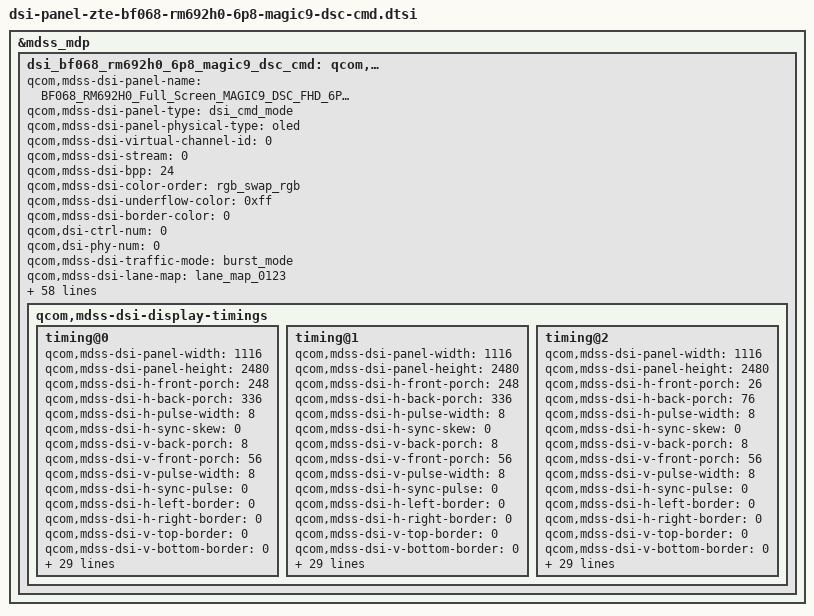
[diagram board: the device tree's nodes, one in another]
&mdss_mdp {
	dsi_bf068_rm692h0_6p8_magic9_dsc_cmd: qcom,mdss_dsi_bf068_rm692h0_6p8_magic9_dsc_cmd {
		qcom,mdss-dsi-panel-name =
				"BF068_RM692H0_Full_Screen_MAGIC9_DSC_FHD_6P8Inch";
		qcom,mdss-dsi-panel-type = "dsi_cmd_mode";
		qcom,mdss-dsi-panel-physical-type = "oled";
		qcom,mdss-dsi-virtual-channel-id = <0>;
		qcom,mdss-dsi-stream = <0>;
		qcom,mdss-dsi-bpp = <24>;
		qcom,mdss-dsi-color-order = "rgb_swap_rgb";
		qcom,mdss-dsi-underflow-color = <0xff>;
		qcom,mdss-dsi-border-color = <0>;
		qcom,dsi-ctrl-num = <0>;
		qcom,dsi-phy-num = <0>;
		qcom,mdss-dsi-traffic-mode = "burst_mode";
		qcom,mdss-dsi-lane-map = "lane_map_0123";
		qcom,mdss-dsi-bllp-eof-power-mode;
		qcom,mdss-dsi-bllp-power-mode;
		qcom,mdss-dsi-lane-0-state;
		qcom,mdss-dsi-lane-1-state;
		qcom,mdss-dsi-lane-2-state;
		qcom,mdss-dsi-lane-3-state;
		qcom,mdss-dsi-lp11-init;
		qcom,mdss-dsi-tx-eot-append;
		qcom,mdss-dsi-dma-trigger = "trigger_sw";
		qcom,mdss-dsi-mdp-trigger = "none";
		qcom,mdss-dsi-reset-sequence = <1 10>, <0 10>, <1 40>;
		qcom,mdss-dsi-te-pin-select = <1>;
		qcom,mdss-dsi-te-dcs-command = <1>;
		qcom,mdss-dsi-te-check-enable;
		qcom,mdss-dsi-te-using-te-pin;
		qcom,mdss-dsi-bl-min-level = <15>;
		qcom,mdss-dsi-bl-max-level = <3515>;
		qcom,mdss-dsi-bl-pmic-control-type = "bl_ctrl_dcs";
		qcom,mdss-dsi-panel-hdr-enabled;
		qcom,mdss-dsi-panel-hdr-color-primaries = <14500 15500 34015
			15980 13030 34670 6950 2565>;
		qcom,mdss-dsi-panel-peak-brightness = <6680000>;
		qcom,mdss-dsi-panel-blackness-level = <20>;
		qcom,mdss-pan-physical-width-dimension = <71>;
		qcom,mdss-pan-physical-height-dimension = <157>;
		qcom,bl-dcs-cmd-state = "dsi_lp_mode";
		qcom,bl-dsc-cmd-state = "dsi_lp_mode";
		qcom,mdss-dsi-display-timings {
			timing@0{
				qcom,mdss-dsi-panel-width = <1116>;
				qcom,mdss-dsi-panel-height = <2480>;
				qcom,mdss-dsi-h-front-porch = <248>;
				qcom,mdss-dsi-h-back-porch = <336>;
				qcom,mdss-dsi-h-pulse-width = <8>;
				qcom,mdss-dsi-h-sync-skew = <0>;
				qcom,mdss-dsi-v-back-porch = <8>;
				qcom,mdss-dsi-v-front-porch = <56>;
				qcom,mdss-dsi-v-pulse-width = <8>;
				qcom,mdss-dsi-h-sync-pulse = <0>;
				qcom,mdss-dsi-h-left-border = <0>;
				qcom,mdss-dsi-h-right-border = <0>;
				qcom,mdss-dsi-v-top-border = <0>;
				qcom,mdss-dsi-v-bottom-border = <0>;
				qcom,mdss-dsi-panel-framerate = <60>;
				qcom,mdss-mdp-transfer-time-us = <6235>;
				/*qcom,mdss-dsi-panel-clockrate = <1124510000>;*/

				qcom,mdss-dsi-on-command = [
					/* dimming */
					39 01 00 00 00 00 02 FE 98
					39 01 00 00 00 00 02 20 03
					/* aod lvd off */
					39 01 00 00 00 00 02 FE 42
					39 01 00 00 00 00 02 68 02
					/* fps 60 */
					39 01 00 00 00 00 02 FE 40
					39 01 00 00 00 00 02 0A C9// C7=60.54 C9=60.25 for 60HZ
					39 01 00 00 00 00 02 0B 17
					39 01 00 00 00 00 02 0C 35
					39 01 00 00 00 00 02 BE C9
					39 01 00 00 00 00 02 BF 11
					39 01 00 00 00 00 02 C0 C9
					39 01 00 00 00 00 02 BD 00
					/* HS CMD OFF */
					15 01 00 00 00 00 02 FE A1
					15 01 00 00 00 00 02 B3 7F
					/* vesa */
					15 01 00 00 00 00 02 FE 00
					15 01 00 00 00 00 02 FA 01
					/* BOE IP EN */
					39 01 00 00 00 00 02 FE 57
					39 01 00 00 00 00 02 C2 48
					39 01 00 00 00 00 02 FE 5A
					39 01 00 00 00 00 02 00 80
					39 01 00 00 00 00 02 FE 1A
					39 01 00 00 00 00 02 0D 64
					39 01 00 00 00 00 02 FE 40
					39 01 00 00 00 00 02 DC B8
					39 01 00 00 00 00 02 FE 42
					39 01 00 00 00 00 02 DA 82
					39 01 00 00 00 00 02 FE 20
					39 01 00 00 00 00 02 81 80
					/* ACL */
					39 01 00 00 00 00 02 FE 34
					39 01 00 00 00 00 02 47 03
					39 01 00 00 00 00 02 48 00
					39 01 00 00 00 00 02 00 00
					39 01 00 00 00 00 02 9F 5C
					39 01 00 00 00 00 02 A0 C4
					39 01 00 00 00 00 02 1C 00
					39 01 00 00 00 00 02 1D 10
					39 01 00 00 00 00 02 49 55
					39 01 00 00 00 00 02 FE 34
					39 01 00 00 00 00 02 1E 00
					39 01 00 00 00 00 02 1F 00
					39 01 00 00 00 00 02 20 00
					39 01 00 00 00 00 02 22 00
					39 01 00 00 00 00 02 21 70
					39 01 00 00 00 00 02 23 F8
					39 01 00 00 00 00 02 24 77
					39 01 00 00 00 00 02 25 F8
					39 01 00 00 00 00 02 26 F8
					39 01 00 00 00 00 02 2F 00
					39 01 00 00 00 00 02 30 00
					39 01 00 00 00 00 02 31 00
					39 01 00 00 00 00 02 32 00
					39 01 00 00 00 00 02 33 00
					39 01 00 00 00 00 02 34 00
					39 01 00 00 00 00 02 35 00
					39 01 00 00 00 00 02 36 40
					39 01 00 00 00 00 02 37 00
					39 01 00 00 00 00 02 38 7F
					39 01 00 00 00 00 02 39 00
					39 01 00 00 00 00 02 3A B6
					39 01 00 00 00 00 02 3B 00
					39 01 00 00 00 00 02 3D 00
					39 01 00 00 00 00 02 3F 00
					39 01 00 00 00 00 02 40 00
					39 01 00 00 00 00 02 41 00
					39 01 00 00 00 00 02 42 00
					/* ESD RECOVER */
					39 01 00 00 00 00 02 FE D4
					39 01 00 00 00 00 02 40 02
					39 01 00 00 00 00 02 FE FD
					39 01 00 00 00 00 02 80 06
					39 01 00 00 00 00 02 83 00
					39 01 00 00 00 00 02 FE A0
					39 01 00 00 00 00 02 06 36
					39 01 00 00 00 00 02 6E 00
					39 01 00 00 00 00 02 7c 15
					39 01 00 00 00 00 02 FE D0
					39 01 00 00 00 00 02 11 75
					39 01 00 00 00 00 02 92 03
					39 01 00 00 00 00 02 FE A1
					39 01 00 00 00 00 02 C3 87
					39 01 00 00 00 00 02 C4 FF
					39 01 00 00 00 00 02 C5 7F
					/* VESA 10bit */
					15 01 00 00 00 00 02 FE 00
					15 01 00 00 00 00 02 FA 01
					15 01 00 00 00 00 02 FE D2
					15 01 00 00 00 00 02 4F 00
					15 01 00 00 00 00 02 50 11
					15 01 00 00 00 00 02 51 ab
					15 01 00 00 00 00 02 52 30
					15 01 00 00 00 00 02 53 09
					15 01 00 00 00 00 02 54 b0
					15 01 00 00 00 00 02 55 04
					15 01 00 00 00 00 02 56 5c
					15 01 00 00 00 00 02 58 00
					15 01 00 00 00 00 02 59 14
					15 01 00 00 00 00 02 5a 02
					15 01 00 00 00 00 02 5b 2e
					15 01 00 00 00 00 02 5c 01
					15 01 00 00 00 00 02 5d 9a
					15 01 00 00 00 00 02 5e 19
					15 01 00 00 00 00 02 5f 01
					15 01 00 00 00 00 02 60 be
					15 01 00 00 00 00 02 61 00
					15 01 00 00 00 00 02 62 0a
					15 01 00 00 00 00 02 63 0c
					15 01 00 00 00 00 02 64 05
					15 01 00 00 00 00 02 65 0e
					15 01 00 00 00 00 02 66 05
					15 01 00 00 00 00 02 67 fd
					15 01 00 00 00 00 02 68 16
					15 01 00 00 00 00 02 69 00
					15 01 00 00 00 00 02 6a 10
					15 01 00 00 00 00 02 6b dc
					15 01 00 00 00 00 02 6c 07
					15 01 00 00 00 00 02 6d 10
					15 01 00 00 00 00 02 6e 20
					15 01 00 00 00 00 02 6f 00
					15 01 00 00 00 00 02 70 06
					15 01 00 00 00 00 02 71 0f
					15 01 00 00 00 00 02 72 0f
					15 01 00 00 00 00 02 73 33
					15 01 00 00 00 00 02 74 0e
					15 01 00 00 00 00 02 75 1c
					15 01 00 00 00 00 02 76 2a
					15 01 00 00 00 00 02 77 38
					15 01 00 00 00 00 02 78 46
					15 01 00 00 00 00 02 79 54
					15 01 00 00 00 00 02 7a 62
					15 01 00 00 00 00 02 7b 69
					15 01 00 00 00 00 02 7c 70
					15 01 00 00 00 00 02 7d 77
					15 01 00 00 00 00 02 7e 79
					15 01 00 00 00 00 02 7f 7b
					15 01 00 00 00 00 02 80 7d
					15 01 00 00 00 00 02 81 7e
					15 01 00 00 00 00 02 82 01
					15 01 00 00 00 00 02 83 c2
					15 01 00 00 00 00 02 84 22
					15 01 00 00 00 00 02 85 00
					15 01 00 00 00 00 02 86 2a
					15 01 00 00 00 00 02 87 40
					15 01 00 00 00 00 02 88 32
					15 01 00 00 00 00 02 89 be
					15 01 00 00 00 00 02 8a 3a
					15 01 00 00 00 00 02 8b fc
					15 01 00 00 00 00 02 8c 3a
					15 01 00 00 00 00 02 8d fa
					15 01 00 00 00 00 02 8e 3a
					15 01 00 00 00 00 02 8f f8
					15 01 00 00 00 00 02 90 3b
					15 01 00 00 00 00 02 91 38
					15 01 00 00 00 00 02 92 3b
					15 01 00 00 00 00 02 93 78
					15 01 00 00 00 00 02 94 3b
					15 01 00 00 00 00 02 95 76
					15 01 00 00 00 00 02 96 4b
					15 01 00 00 00 00 02 97 b6
					15 01 00 00 00 00 02 98 4b
					15 01 00 00 00 00 02 99 f6
					15 01 00 00 00 00 02 9a 4c
					15 01 00 00 00 00 02 9b 34
					15 01 00 00 00 00 02 9c 5c
					15 01 00 00 00 00 02 9d 74
					15 01 00 00 00 00 02 9e 8c
					15 01 00 00 00 00 02 9f f4
					15 01 00 00 00 00 02 a2 02
					15 01 00 00 00 00 02 a3 ba
					15 01 00 00 00 00 02 a4 00
					15 01 00 00 00 00 02 a5 00
					15 01 00 00 00 00 02 a6 00
					15 01 00 00 00 00 02 a7 00
					15 01 00 00 00 00 02 a9 00
					15 01 00 00 00 00 02 aa 00
					15 01 00 00 00 00 02 a0 a0
					/* ST swire control */
					15 01 00 00 00 00 02 FE 40
					15 01 00 00 00 00 02 24 54
					15 01 00 00 00 00 02 A9 14
					15 01 00 00 00 00 02 AD C8
					15 01 00 00 00 00 02 A5 20
					15 01 00 00 00 00 02 AC 04
					15 01 00 00 00 00 02 AE 70
					15 01 00 00 00 00 02 AF 4B
					15 01 00 00 00 00 02 B0 4B
					15 01 00 00 00 00 02 B2 4B
					15 01 00 00 00 00 02 B3 4F
					15 01 00 00 00 00 02 FE 26
					15 01 00 00 00 00 02 1D 26
					15 01 00 00 00 00 02 A4 1F
					/*8.8 PVGH*/
					15 01 00 00 00 00 02 FE 40
					15 01 00 00 00 00 02 3A E8
 					15 01 00 00 00 00 02 3B E8
					15 01 00 00 00 00 02 FE 42
					15 01 00 00 00 00 02 81 E8
					15 01 00 00 00 00 02 82 E8
					/* init code */
					15 01 00 00 00 00 02 FE 00
					15 01 00 00 00 00 02 C2 08
					15 01 00 00 00 00 02 36 00
					15 01 00 00 00 00 02 35 00
					15 01 00 00 00 00 02 53 20
					39 01 00 00 00 00 03 51 00 00
15 01 00 00 00 00 02 FE 60
15 01 00 00 00 00 02 AE 00
15 01 00 00 00 00 02 B3 00
15 01 00 00 00 00 02 B8 FF
15 01 00 00 00 00 02 BA FF
15 01 00 00 00 00 02 C7 CB
15 01 00 00 00 00 02 C8 CB
15 01 00 00 00 00 02 DB CB
15 01 00 00 00 00 02 DC CB
15 01 00 00 00 00 02 FE 00
					05 01 00 00 64 00 01 11
					05 01 00 00 14 00 01 29
					];
				qcom,mdss-dsi-off-command = [
15 01 00 00 00 00 02 FE 76
15 01 00 00 00 00 02 00 04

15 01 00 00 00 00 02 09 28
15 01 00 00 00 00 02 0A 00
15 01 00 00 00 00 02 0B 00
15 01 00 00 00 00 02 0C 49
15 01 00 00 00 00 02 0D 76
15 01 00 00 00 00 02 0E 17

15 01 00 00 00 00 02 49 FF
15 01 00 00 00 00 02 4A 01
15 01 00 00 00 00 02 4B 01
15 01 00 00 00 00 02 4C FE
15 01 00 00 00 00 02 4D 60
15 01 00 00 00 00 02 4E AE
15 01 00 00 00 00 02 4F 28
15 01 00 00 00 00 02 50 B3
15 01 00 00 00 00 02 51 28
15 01 00 00 00 00 02 52 B8
15 01 00 00 00 00 02 53 F9
15 01 00 00 00 00 02 54 BA
15 01 00 00 00 00 02 55 9F
15 01 00 00 00 00 02 56 C7
15 01 00 00 00 00 02 58 CF
15 01 00 00 00 00 02 59 C8
15 01 00 00 00 00 02 5A CF
15 01 00 00 00 00 02 5B DB
15 01 00 00 00 00 02 5C CF
15 01 00 00 00 00 02 5D DC
15 01 00 00 00 00 02 5E CF
15 01 00 00 00 00 02 5F FE
15 01 00 00 00 00 02 60 00
					15 01 00 00 14 00 02 FE 00
					05 01 00 00 93 00 01 28
					05 01 00 00 14 00 01 10
				];
				qcom,mdss-dsi-on-command-state = "dsi_lp_mode";
				qcom,mdss-dsi-off-command-state = "dsi_lp_mode";

				qcom,mdss-dsi-lp1-command = [
					15 01 00 00 00 00 02 FE 00
					05 01 00 00 14 00 01 39
				];
				qcom,mdss-dsi-lp1-command-state =
					"dsi_lp_mode";
				qcom,mdss-dsi-nolp-command = [
					15 01 00 00 00 00 02 FE 00
					39 01 00 00 00 00 03 51 00 00
					05 01 00 00 00 00 01 38
				];
				qcom,mdss-dsi-nolp-command-state =
					"dsi_lp_mode";
				qcom,mdss-dsi-timing-switch-command = [
					39 00 00 40 00 00 02 FE 40
					39 00 00 40 00 00 02 bd 00
					39 00 00 40 00 00 02 FE 5A
					39 00 00 40 00 00 0D 49 5E FF F0 FF FF FF F0 FF FF 00 FD FD
					39 00 00 40 00 00 03 58 16 FA
					39 00 00 40 00 00 05 5E 0F 0F 0F 05
					39 00 00 40 00 00 04 66 00 00 00
					39 00 00 40 00 00 03 6E 00 00
					39 00 00 40 00 00 03 7E 00 00
					39 00 00 40 00 00 04 92 4E 22 1F
					39 00 00 40 00 00 05 99 2D 24 0C 00
					39 00 00 40 00 00 04 9E 20 20 20
					39 00 00 40 00 00 03 A2 10 03
					39 00 00 40 00 00 02 A7 10
					39 00 00 40 00 00 03 A9 10 0D
					39 00 00 40 00 00 02 AC 00
					39 00 00 40 00 00 06 B0 08 08 05 05 00
					39 00 00 40 00 00 06 B8 09 09 05 00 00
					39 00 00 40 00 00 05 C0 08 08 03 00
					39 00 00 40 00 00 04 C8 06 06 02
					39 00 00 40 00 00 02 EA 16
					39 00 00 40 00 00 02 FE 5B
					39 00 00 40 00 00 02 2B 4B
					39 00 00 40 00 00 02 2D 24
					39 00 00 40 00 00 02 2F 1F
					39 00 00 40 00 00 0D 30 1F 3F 3F 38 32 24 0C 00 00 25 25 1D
					39 00 00 40 00 00 02 3D 11
					39 00 00 40 00 00 02 3F 07
					39 00 00 40 00 00 0A 40 04 00 00 1A 1A 0E 08 03 00
					39 00 00 40 00 00 05 4B 08 08 08 08
					39 00 00 40 00 00 02 50 00
					39 00 00 40 00 00 05 53 09 09 05 02
					39 00 00 40 00 00 02 58 00
					39 00 00 40 00 00 06 5C 08 08 04 01 00
					39 00 00 40 00 00 05 64 07 07 03 01
					39 00 00 00 00 00 02 FE 00
				];
				qcom,mdss-dsi-timing-switch-command-state =
				"dsi_lp_mode";
				qcom,compression-mode = "dsc";
				qcom,mdss-dsc-slice-height = <20>;
				qcom,mdss-dsc-slice-width = <558>;
				qcom,mdss-dsc-slice-per-pkt = <2>;
				qcom,mdss-dsc-bit-per-component = <10>;
				qcom,mdss-dsc-bit-per-pixel = <10>;
				qcom,mdss-dsc-block-prediction-enable;
			};
			timing@1{
				qcom,mdss-dsi-panel-width = <1116>;
				qcom,mdss-dsi-panel-height = <2480>;
				qcom,mdss-dsi-h-front-porch = <248>;
				qcom,mdss-dsi-h-back-porch = <336>;
				qcom,mdss-dsi-h-pulse-width = <8>;
				qcom,mdss-dsi-h-sync-skew = <0>;
				qcom,mdss-dsi-v-back-porch = <8>;
				qcom,mdss-dsi-v-front-porch = <56>;
				qcom,mdss-dsi-v-pulse-width = <8>;
				qcom,mdss-dsi-h-sync-pulse = <0>;
				qcom,mdss-dsi-h-left-border = <0>;
				qcom,mdss-dsi-h-right-border = <0>;
				qcom,mdss-dsi-v-top-border = <0>;
				qcom,mdss-dsi-v-bottom-border = <0>;
				qcom,mdss-dsi-panel-framerate = <90>;
				qcom,mdss-mdp-transfer-time-us = <6235>;
				/*qcom,mdss-dsi-panel-clockrate = <1124510000>;*/

				qcom,mdss-dsi-on-command = [
					/* dimming */
					39 01 00 00 00 00 02 FE 98
					39 01 00 00 00 00 02 20 03
					/* aod lvd off */
					39 01 00 00 00 00 02 FE 42
					39 01 00 00 00 00 02 68 02
					/* fps 90 */
					39 01 00 00 00 00 02 FE 40
					39 01 00 00 00 00 02 0A C9
					39 01 00 00 00 00 02 0B 17
					39 01 00 00 00 00 02 0C 35
					39 01 00 00 00 00 02 BE C9
					39 01 00 00 00 00 02 BF 11
					39 01 00 00 00 00 02 C0 C9
					39 01 00 00 00 00 02 BD 06
					/* HS CMD OFF */
					15 01 00 00 00 00 02 FE A1
					15 01 00 00 00 00 02 B3 7F
					/* vesa */
					15 01 00 00 00 00 02 FE 00
					15 01 00 00 00 00 02 FA 01
					/* BOE IP EN */
					39 01 00 00 00 00 02 FE 57
					39 01 00 00 00 00 02 C2 48
					39 01 00 00 00 00 02 FE 5A
					39 01 00 00 00 00 02 00 80
					39 01 00 00 00 00 02 FE 1A
					39 01 00 00 00 00 02 0D 64
					39 01 00 00 00 00 02 FE 40
					39 01 00 00 00 00 02 DC B8
					39 01 00 00 00 00 02 FE 42
					39 01 00 00 00 00 02 DA 82
					39 01 00 00 00 00 02 FE 20
					39 01 00 00 00 00 02 81 80
					/* ACL */
					39 01 00 00 00 00 02 FE 34
					39 01 00 00 00 00 02 47 03
					39 01 00 00 00 00 02 48 00
					39 01 00 00 00 00 02 00 00
					39 01 00 00 00 00 02 9F 5C
					39 01 00 00 00 00 02 A0 C4
					39 01 00 00 00 00 02 1C 00
					39 01 00 00 00 00 02 1D 10
					39 01 00 00 00 00 02 49 55
					39 01 00 00 00 00 02 FE 34
					39 01 00 00 00 00 02 1E 00
					39 01 00 00 00 00 02 1F 00
					39 01 00 00 00 00 02 20 00
					39 01 00 00 00 00 02 22 00
					39 01 00 00 00 00 02 21 70
					39 01 00 00 00 00 02 23 F8
					39 01 00 00 00 00 02 24 77
					39 01 00 00 00 00 02 25 F8
					39 01 00 00 00 00 02 26 F8
					39 01 00 00 00 00 02 2F 00
					39 01 00 00 00 00 02 30 00
					39 01 00 00 00 00 02 31 00
					39 01 00 00 00 00 02 32 00
					39 01 00 00 00 00 02 33 00
					39 01 00 00 00 00 02 34 00
					39 01 00 00 00 00 02 35 00
					39 01 00 00 00 00 02 36 40
					39 01 00 00 00 00 02 37 00
					39 01 00 00 00 00 02 38 7F
					39 01 00 00 00 00 02 39 00
					39 01 00 00 00 00 02 3A B6
					39 01 00 00 00 00 02 3B 00
					39 01 00 00 00 00 02 3D 00
					39 01 00 00 00 00 02 3F 00
					39 01 00 00 00 00 02 40 00
					39 01 00 00 00 00 02 41 00
					39 01 00 00 00 00 02 42 00
					/* ESD RECOVER */
					39 01 00 00 00 00 02 FE D4
					39 01 00 00 00 00 02 40 02
					39 01 00 00 00 00 02 FE FD
					39 01 00 00 00 00 02 80 06
					39 01 00 00 00 00 02 83 00
					39 01 00 00 00 00 02 FE A0
					39 01 00 00 00 00 02 06 36
					39 01 00 00 00 00 02 6E 00
					39 01 00 00 00 00 02 7c 15
					39 01 00 00 00 00 02 FE D0
					39 01 00 00 00 00 02 11 75
					39 01 00 00 00 00 02 92 03
					39 01 00 00 00 00 02 FE A1
					39 01 00 00 00 00 02 C3 87
					39 01 00 00 00 00 02 C4 FF
					39 01 00 00 00 00 02 C5 7F
					/* VESA 10bit */
					15 01 00 00 00 00 02 FE 00
					15 01 00 00 00 00 02 FA 01
					15 01 00 00 00 00 02 FE D2
					15 01 00 00 00 00 02 4F 00
					15 01 00 00 00 00 02 50 11
					15 01 00 00 00 00 02 51 ab
					15 01 00 00 00 00 02 52 30
					15 01 00 00 00 00 02 53 09
					15 01 00 00 00 00 02 54 b0
					15 01 00 00 00 00 02 55 04
					15 01 00 00 00 00 02 56 5c
					15 01 00 00 00 00 02 58 00
					15 01 00 00 00 00 02 59 14
					15 01 00 00 00 00 02 5a 02
					15 01 00 00 00 00 02 5b 2e
					15 01 00 00 00 00 02 5c 01
					15 01 00 00 00 00 02 5d 9a
					15 01 00 00 00 00 02 5e 19
					15 01 00 00 00 00 02 5f 01
					15 01 00 00 00 00 02 60 be
					15 01 00 00 00 00 02 61 00
					15 01 00 00 00 00 02 62 0a
					15 01 00 00 00 00 02 63 0c
					15 01 00 00 00 00 02 64 05
					15 01 00 00 00 00 02 65 0e
					15 01 00 00 00 00 02 66 05
					15 01 00 00 00 00 02 67 fd
					15 01 00 00 00 00 02 68 16
					15 01 00 00 00 00 02 69 00
					15 01 00 00 00 00 02 6a 10
					15 01 00 00 00 00 02 6b dc
					15 01 00 00 00 00 02 6c 07
					15 01 00 00 00 00 02 6d 10
					15 01 00 00 00 00 02 6e 20
					15 01 00 00 00 00 02 6f 00
					15 01 00 00 00 00 02 70 06
					15 01 00 00 00 00 02 71 0f
					15 01 00 00 00 00 02 72 0f
					15 01 00 00 00 00 02 73 33
					15 01 00 00 00 00 02 74 0e
					15 01 00 00 00 00 02 75 1c
					15 01 00 00 00 00 02 76 2a
					15 01 00 00 00 00 02 77 38
					15 01 00 00 00 00 02 78 46
					15 01 00 00 00 00 02 79 54
					15 01 00 00 00 00 02 7a 62
					15 01 00 00 00 00 02 7b 69
					15 01 00 00 00 00 02 7c 70
					15 01 00 00 00 00 02 7d 77
					15 01 00 00 00 00 02 7e 79
					15 01 00 00 00 00 02 7f 7b
					15 01 00 00 00 00 02 80 7d
					15 01 00 00 00 00 02 81 7e
					15 01 00 00 00 00 02 82 01
					15 01 00 00 00 00 02 83 c2
					15 01 00 00 00 00 02 84 22
					15 01 00 00 00 00 02 85 00
					15 01 00 00 00 00 02 86 2a
					15 01 00 00 00 00 02 87 40
					15 01 00 00 00 00 02 88 32
					15 01 00 00 00 00 02 89 be
					15 01 00 00 00 00 02 8a 3a
					15 01 00 00 00 00 02 8b fc
					15 01 00 00 00 00 02 8c 3a
					15 01 00 00 00 00 02 8d fa
					15 01 00 00 00 00 02 8e 3a
					15 01 00 00 00 00 02 8f f8
					15 01 00 00 00 00 02 90 3b
					15 01 00 00 00 00 02 91 38
					15 01 00 00 00 00 02 92 3b
					15 01 00 00 00 00 02 93 78
					15 01 00 00 00 00 02 94 3b
					15 01 00 00 00 00 02 95 76
					15 01 00 00 00 00 02 96 4b
					15 01 00 00 00 00 02 97 b6
					15 01 00 00 00 00 02 98 4b
					15 01 00 00 00 00 02 99 f6
					15 01 00 00 00 00 02 9a 4c
					15 01 00 00 00 00 02 9b 34
					15 01 00 00 00 00 02 9c 5c
					15 01 00 00 00 00 02 9d 74
					15 01 00 00 00 00 02 9e 8c
					15 01 00 00 00 00 02 9f f4
					15 01 00 00 00 00 02 a2 02
					15 01 00 00 00 00 02 a3 ba
					15 01 00 00 00 00 02 a4 00
					15 01 00 00 00 00 02 a5 00
					15 01 00 00 00 00 02 a6 00
					15 01 00 00 00 00 02 a7 00
					15 01 00 00 00 00 02 a9 00
					15 01 00 00 00 00 02 aa 00
					15 01 00 00 00 00 02 a0 a0
					/* ST swire control */
					15 01 00 00 00 00 02 FE 40
					15 01 00 00 00 00 02 24 54
					15 01 00 00 00 00 02 A9 14
					15 01 00 00 00 00 02 AD C8
					15 01 00 00 00 00 02 A5 20
					15 01 00 00 00 00 02 AC 04
					15 01 00 00 00 00 02 AE 70
					15 01 00 00 00 00 02 AF 4B
					15 01 00 00 00 00 02 B0 4B
					15 01 00 00 00 00 02 B2 4B
					15 01 00 00 00 00 02 B3 4F
					15 01 00 00 00 00 02 FE 26
					15 01 00 00 00 00 02 1D 26
					15 01 00 00 00 00 02 A4 1F
					/*8.8 PVGH*/
					15 01 00 00 00 00 02 FE 40
					15 01 00 00 00 00 02 3A E8
 					15 01 00 00 00 00 02 3B E8
					15 01 00 00 00 00 02 FE 42
					15 01 00 00 00 00 02 81 E8
					15 01 00 00 00 00 02 82 E8
					/* init code */
					15 01 00 00 00 00 02 FE 00
					15 01 00 00 00 00 02 C2 08
					15 01 00 00 00 00 02 36 00
					15 01 00 00 00 00 02 35 00
					15 01 00 00 00 00 02 53 20
					39 01 00 00 00 00 03 51 00 00
15 01 00 00 00 00 02 FE 60
15 01 00 00 00 00 02 AE 00
15 01 00 00 00 00 02 B3 00
15 01 00 00 00 00 02 B8 FF
15 01 00 00 00 00 02 BA FF
15 01 00 00 00 00 02 C7 CB
15 01 00 00 00 00 02 C8 CB
15 01 00 00 00 00 02 DB CB
15 01 00 00 00 00 02 DC CB
15 01 00 00 00 00 02 FE 00
					05 01 00 00 64 00 01 11
					05 01 00 00 14 00 01 29
					];
				qcom,mdss-dsi-off-command = [
15 01 00 00 00 00 02 FE 76
15 01 00 00 00 00 02 00 04

15 01 00 00 00 00 02 09 28
15 01 00 00 00 00 02 0A 00
15 01 00 00 00 00 02 0B 00
15 01 00 00 00 00 02 0C 49
15 01 00 00 00 00 02 0D 76
15 01 00 00 00 00 02 0E 17

15 01 00 00 00 00 02 49 FF
15 01 00 00 00 00 02 4A 01
15 01 00 00 00 00 02 4B 01
15 01 00 00 00 00 02 4C FE
15 01 00 00 00 00 02 4D 60
15 01 00 00 00 00 02 4E AE
15 01 00 00 00 00 02 4F 28
15 01 00 00 00 00 02 50 B3
15 01 00 00 00 00 02 51 28
15 01 00 00 00 00 02 52 B8
15 01 00 00 00 00 02 53 F9
15 01 00 00 00 00 02 54 BA
15 01 00 00 00 00 02 55 9F
15 01 00 00 00 00 02 56 C7
15 01 00 00 00 00 02 58 CF
15 01 00 00 00 00 02 59 C8
15 01 00 00 00 00 02 5A CF
15 01 00 00 00 00 02 5B DB
15 01 00 00 00 00 02 5C CF
15 01 00 00 00 00 02 5D DC
15 01 00 00 00 00 02 5E CF
15 01 00 00 00 00 02 5F FE
15 01 00 00 00 00 02 60 00
					15 01 00 00 14 00 02 FE 00
					05 01 00 00 93 00 01 28
					05 01 00 00 14 00 01 10
				];
				qcom,mdss-dsi-on-command-state = "dsi_lp_mode";
				qcom,mdss-dsi-off-command-state = "dsi_lp_mode";

				qcom,mdss-dsi-lp1-command = [
					15 01 00 00 00 00 02 FE 00
					05 01 00 00 14 00 01 39
				];
				qcom,mdss-dsi-lp1-command-state =
					"dsi_lp_mode";
				qcom,mdss-dsi-nolp-command = [
					15 01 00 00 00 00 02 FE 00
					39 01 00 00 00 00 03 51 00 00
					05 01 00 00 00 00 01 38
				];
				qcom,mdss-dsi-nolp-command-state =
					"dsi_lp_mode";
				qcom,mdss-dsi-timing-switch-command = [
					39 00 00 40 00 00 02 FE 40
					39 00 00 40 00 00 02 BD 06
					39 00 00 40 00 00 02 FE 5A
					39 00 00 40 00 00 0B 49 0F 08 04 00 06 06 06 06 06 04
					39 00 00 40 00 00 03 55 03 03
					39 00 00 40 00 00 0A 58 03 03 0F 0F 0F 0A 10 10 10
					39 00 00 40 00 00 03 6E 0A 0A
					39 00 00 40 00 00 03 76 0A 0A
					39 00 00 40 00 00 03 7E 0A 0A
					39 00 00 40 00 00 04 92 7F 3A 25
					39 00 00 40 00 00 05 99 2D 30 0F 03
					39 00 00 40 00 00 04 9E 20 20 20
					39 00 00 40 00 00 03 A2 25 0E
					39 00 00 40 00 00 02 A7 10
					39 00 00 40 00 00 03 A9 10 15
					39 00 00 40 00 00 02 AC 00
					39 00 00 40 00 00 06 B0 08 08 0A 05 03
					39 00 00 40 00 00 06 B8 0F 0F 0D 03 00
					39 00 00 40 00 00 05 C0 0A 0A 06 01
					39 00 00 40 00 00 04 C8 09 09 05
					39 00 00 40 00 00 02 EA 16
					39 00 00 40 00 00 02 FE 5B
					39 00 00 40 00 00 02 2B 6A
					39 00 00 40 00 00 02 2D 3F
					39 00 00 40 00 00 0E 2F 2F 7A 3F 3F 38 2F 30 15 0A 0A 25 25 1B 
					39 00 00 40 00 00 02 3D 1F
					39 00 00 40 00 00 0B 3F 0F 07 02 01 1A 1A 16 0A 04 01
					39 00 00 40 00 00 05 4B 08 08 09 06
					39 00 00 40 00 00 02 50 00
					39 00 00 40 00 00 05 53 0C 0C 0A 05
					39 00 00 40 00 00 02 58 01
					39 00 00 40 00 00 06 5C 08 08 06 02 01
					39 00 00 40 00 00 05 64 07 07 04 02
					39 00 00 00 00 00 02 FE 00
				];
				qcom,mdss-dsi-timing-switch-command-state =
				"dsi_lp_mode";
				qcom,compression-mode = "dsc";
				qcom,mdss-dsc-slice-height = <20>;
				qcom,mdss-dsc-slice-width = <558>;
				qcom,mdss-dsc-slice-per-pkt = <2>;
				qcom,mdss-dsc-bit-per-component = <10>;
				qcom,mdss-dsc-bit-per-pixel = <10>;
				qcom,mdss-dsc-block-prediction-enable;
			};
			timing@2{
				qcom,mdss-dsi-panel-width = <1116>;
				qcom,mdss-dsi-panel-height = <2480>;
				qcom,mdss-dsi-h-front-porch = <26>;
				qcom,mdss-dsi-h-back-porch = <76>;
				qcom,mdss-dsi-h-pulse-width = <8>;
				qcom,mdss-dsi-h-sync-skew = <0>;
				qcom,mdss-dsi-v-back-porch = <8>;
				qcom,mdss-dsi-v-front-porch = <56>;
				qcom,mdss-dsi-v-pulse-width = <8>;
				qcom,mdss-dsi-h-sync-pulse = <0>;
				qcom,mdss-dsi-h-left-border = <0>;
				qcom,mdss-dsi-h-right-border = <0>;
				qcom,mdss-dsi-v-top-border = <0>;
				qcom,mdss-dsi-v-bottom-border = <0>;
				qcom,mdss-dsi-panel-framerate = <120>;
				qcom,mdss-mdp-transfer-time-us = <6235>;
				/*qcom,mdss-dsi-panel-clockrate = <1124510000>;*/

				qcom,mdss-dsi-on-command = [
					39 01 00 00 00 00 02 FE 98
					39 01 00 00 00 00 02 20 03
					/* aod lvd off */
					39 01 00 00 00 00 02 FE 42
					39 01 00 00 00 00 02 68 02
					/* fps 120 */
					39 01 00 00 00 00 02 FE 40
					39 01 00 00 00 00 02 0A C9
					39 01 00 00 00 00 02 0B 17
					39 01 00 00 00 00 02 0C 35
					39 01 00 00 00 00 02 BE C9
					39 01 00 00 00 00 02 BF 11
					39 01 00 00 00 00 02 C0 C9
					39 01 00 00 00 00 02 BD 05
					/* HS CMD OFF */
					15 01 00 00 00 00 02 FE A1
					15 01 00 00 00 00 02 B3 7F
					/* vesa */
					15 01 00 00 00 00 02 FE 00
					15 01 00 00 00 00 02 FA 01
					/* BOE IP EN */
					39 01 00 00 00 00 02 FE 57
					39 01 00 00 00 00 02 C2 48
					39 01 00 00 00 00 02 FE 5A
					39 01 00 00 00 00 02 00 80
					39 01 00 00 00 00 02 FE 1A
					39 01 00 00 00 00 02 0D 64
					39 01 00 00 00 00 02 FE 40
					39 01 00 00 00 00 02 DC B8
					39 01 00 00 00 00 02 FE 42
					39 01 00 00 00 00 02 DA 82
					39 01 00 00 00 00 02 FE 20
					39 01 00 00 00 00 02 81 80
					/* ACL */
					39 01 00 00 00 00 02 FE 34
					39 01 00 00 00 00 02 47 03
					39 01 00 00 00 00 02 48 00
					39 01 00 00 00 00 02 00 00
					39 01 00 00 00 00 02 9F 5C
					39 01 00 00 00 00 02 A0 C4
					39 01 00 00 00 00 02 1C 00
					39 01 00 00 00 00 02 1D 10
					39 01 00 00 00 00 02 49 55
					39 01 00 00 00 00 02 FE 34
					39 01 00 00 00 00 02 1E 00
					39 01 00 00 00 00 02 1F 00
					39 01 00 00 00 00 02 20 00
					39 01 00 00 00 00 02 22 00
					39 01 00 00 00 00 02 21 70
					39 01 00 00 00 00 02 23 F8
					39 01 00 00 00 00 02 24 77
					39 01 00 00 00 00 02 25 F8
					39 01 00 00 00 00 02 26 F8
					39 01 00 00 00 00 02 2F 00
					39 01 00 00 00 00 02 30 00
					39 01 00 00 00 00 02 31 00
					39 01 00 00 00 00 02 32 00
					39 01 00 00 00 00 02 33 00
					39 01 00 00 00 00 02 34 00
					39 01 00 00 00 00 02 35 00
					39 01 00 00 00 00 02 36 40
					39 01 00 00 00 00 02 37 00
					39 01 00 00 00 00 02 38 7F
					39 01 00 00 00 00 02 39 00
					39 01 00 00 00 00 02 3A B6
					39 01 00 00 00 00 02 3B 00
					39 01 00 00 00 00 02 3D 00
					39 01 00 00 00 00 02 3F 00
					39 01 00 00 00 00 02 40 00
					39 01 00 00 00 00 02 41 00
					39 01 00 00 00 00 02 42 00
					/* ESD RECOVER */
					39 01 00 00 00 00 02 FE D4
					39 01 00 00 00 00 02 40 02
					39 01 00 00 00 00 02 FE FD
					39 01 00 00 00 00 02 80 06
					39 01 00 00 00 00 02 83 00
					39 01 00 00 00 00 02 FE A0
					39 01 00 00 00 00 02 06 36
					39 01 00 00 00 00 02 6E 00
					39 01 00 00 00 00 02 7C 15
					39 01 00 00 00 00 02 FE D0
					39 01 00 00 00 00 02 11 75
					39 01 00 00 00 00 02 92 03
					39 01 00 00 00 00 02 FE A1
					39 01 00 00 00 00 02 C3 87
					39 01 00 00 00 00 02 C4 FF
					39 01 00 00 00 00 02 C5 7F
					/* VESA 10bit */
					15 01 00 00 00 00 02 FE 00
					15 01 00 00 00 00 02 FA 01
					15 01 00 00 00 00 02 FE D2
					15 01 00 00 00 00 02 4F 00
					15 01 00 00 00 00 02 50 11
					15 01 00 00 00 00 02 51 ab
					15 01 00 00 00 00 02 52 30
					15 01 00 00 00 00 02 53 09
					15 01 00 00 00 00 02 54 b0
					15 01 00 00 00 00 02 55 04
					15 01 00 00 00 00 02 56 5c
					15 01 00 00 00 00 02 58 00
					15 01 00 00 00 00 02 59 14
					15 01 00 00 00 00 02 5a 02
					15 01 00 00 00 00 02 5b 2e
					15 01 00 00 00 00 02 5c 01
					15 01 00 00 00 00 02 5d 9a
					15 01 00 00 00 00 02 5e 19
					15 01 00 00 00 00 02 5f 01
					15 01 00 00 00 00 02 60 be
					15 01 00 00 00 00 02 61 00
					15 01 00 00 00 00 02 62 0a
					15 01 00 00 00 00 02 63 0c
					15 01 00 00 00 00 02 64 05
					15 01 00 00 00 00 02 65 0e
					15 01 00 00 00 00 02 66 05
					15 01 00 00 00 00 02 67 fd
					15 01 00 00 00 00 02 68 16
					15 01 00 00 00 00 02 69 00
					15 01 00 00 00 00 02 6a 10
					15 01 00 00 00 00 02 6b dc
					15 01 00 00 00 00 02 6c 07
					15 01 00 00 00 00 02 6d 10
					15 01 00 00 00 00 02 6e 20
					15 01 00 00 00 00 02 6f 00
					15 01 00 00 00 00 02 70 06
					15 01 00 00 00 00 02 71 0f
					15 01 00 00 00 00 02 72 0f
					15 01 00 00 00 00 02 73 33
					15 01 00 00 00 00 02 74 0e
					15 01 00 00 00 00 02 75 1c
					15 01 00 00 00 00 02 76 2a
					15 01 00 00 00 00 02 77 38
					15 01 00 00 00 00 02 78 46
					15 01 00 00 00 00 02 79 54
					15 01 00 00 00 00 02 7a 62
					15 01 00 00 00 00 02 7b 69
					15 01 00 00 00 00 02 7c 70
					15 01 00 00 00 00 02 7d 77
					15 01 00 00 00 00 02 7e 79
					15 01 00 00 00 00 02 7f 7b
					15 01 00 00 00 00 02 80 7d
					15 01 00 00 00 00 02 81 7e
					15 01 00 00 00 00 02 82 01
					15 01 00 00 00 00 02 83 c2
					15 01 00 00 00 00 02 84 22
					15 01 00 00 00 00 02 85 00
					15 01 00 00 00 00 02 86 2a
					15 01 00 00 00 00 02 87 40
					15 01 00 00 00 00 02 88 32
					15 01 00 00 00 00 02 89 be
					15 01 00 00 00 00 02 8a 3a
					15 01 00 00 00 00 02 8b fc
					15 01 00 00 00 00 02 8c 3a
					15 01 00 00 00 00 02 8d fa
					15 01 00 00 00 00 02 8e 3a
					15 01 00 00 00 00 02 8f f8
					15 01 00 00 00 00 02 90 3b
					15 01 00 00 00 00 02 91 38
					15 01 00 00 00 00 02 92 3b
					15 01 00 00 00 00 02 93 78
					15 01 00 00 00 00 02 94 3b
					15 01 00 00 00 00 02 95 76
					15 01 00 00 00 00 02 96 4b
					15 01 00 00 00 00 02 97 b6
					15 01 00 00 00 00 02 98 4b
					15 01 00 00 00 00 02 99 f6
					15 01 00 00 00 00 02 9a 4c
					15 01 00 00 00 00 02 9b 34
					15 01 00 00 00 00 02 9c 5c
					15 01 00 00 00 00 02 9d 74
					15 01 00 00 00 00 02 9e 8c
					15 01 00 00 00 00 02 9f f4
					15 01 00 00 00 00 02 a2 02
					15 01 00 00 00 00 02 a3 ba
					15 01 00 00 00 00 02 a4 00
					15 01 00 00 00 00 02 a5 00
					15 01 00 00 00 00 02 a6 00
					15 01 00 00 00 00 02 a7 00
					15 01 00 00 00 00 02 a9 00
					15 01 00 00 00 00 02 aa 00
					15 01 00 00 00 00 02 a0 a0
					/* 120fps black line */
					39 01 00 00 00 00 02 FE 5A
					39 01 00 00 00 00 0B 49 0F 08 04 00 06 06 06 06 06 04
					39 01 00 00 00 00 03 55 10 10
					39 01 00 00 00 00 03 58 05 03
					39 01 00 00 00 00 05 5E 0F 0F 0F 0A
					39 01 00 00 00 00 04 66 10 10 10
					39 01 00 00 00 00 03 6E 05 05
					39 01 00 00 00 00 03 76 05 05
					39 01 00 00 00 00 03 7E 05 05
					39 01 00 00 00 00 04 92 72 45 25
					39 01 00 00 00 00 05 99 7F 40 0F 03
					39 01 00 00 00 00 04 9E 30 10 3D
					39 01 00 00 00 00 03 A2 1D 09
					39 01 00 00 00 00 02 A7 27
					39 01 00 00 00 00 03 A9 27 1A
					39 01 00 00 00 00 02 AC 04
					39 01 00 00 00 00 06 B0 20 10 0A 0D 03
					39 01 00 00 00 00 06 B8 12 12 0D 03 02
					39 01 00 00 00 00 05 C0 0E 0E 09 03
					39 01 00 00 00 00 04 C8 0B 0B 07
					39 01 00 00 00 00 02 EA 1F
					39 01 00 00 00 00 02 FE 5B
					39 01 00 00 00 00 02 2B 7A
					39 01 00 00 00 00 02 2D 45
					39 01 00 00 00 00 02 2F 32
					39 01 00 00 00 00 0D 31 60 1F 60 60 60 37 18 0F 0A 30 30 2B
					39 01 00 00 00 00 02 3D 1F
					39 01 00 00 00 00 0B 3F 0F 07 02 01 1B 1B 1B 0E 06 02
					39 01 00 00 00 00 05 4B 13 13 0D 09
					39 01 00 00 00 00 02 50 01
					39 01 00 00 00 00 05 53 12 12 0B 05
					39 01 00 00 00 00 02 58 03
					39 01 00 00 00 00 06 5C 0B 0D 08 04 02
					39 01 00 00 00 00 06 5C 0B 00 08 04 02
					39 01 00 00 00 00 05 64 09 09 06 02
					/* ST swire control */
					15 01 00 00 00 00 02 FE 40
					15 01 00 00 00 00 02 24 54
					15 01 00 00 00 00 02 A9 14
					15 01 00 00 00 00 02 AD C8
					15 01 00 00 00 00 02 A5 20
					15 01 00 00 00 00 02 AC 04
					15 01 00 00 00 00 02 AE 70
					15 01 00 00 00 00 02 AF 4B
					15 01 00 00 00 00 02 B0 4B
					15 01 00 00 00 00 02 B2 4B
					15 01 00 00 00 00 02 B3 4F
					15 01 00 00 00 00 02 FE 26
					15 01 00 00 00 00 02 1D 26
					15 01 00 00 00 00 02 A4 1F
					/*8.8 PVGH*/
					15 01 00 00 00 00 02 FE 40
					15 01 00 00 00 00 02 3A E8
 					15 01 00 00 00 00 02 3B E8
					15 01 00 00 00 00 02 FE 42
					15 01 00 00 00 00 02 81 E8
					15 01 00 00 00 00 02 82 E8
					/* init code */
					15 01 00 00 00 00 02 FE 00
					15 01 00 00 00 00 02 C2 08
					15 01 00 00 00 00 02 36 00
					15 01 00 00 00 00 02 35 00
					15 01 00 00 00 00 02 53 20
					39 01 00 00 00 00 03 51 00 00
15 01 00 00 00 00 02 FE 60
15 01 00 00 00 00 02 AE 00
15 01 00 00 00 00 02 B3 00
15 01 00 00 00 00 02 B8 FF
15 01 00 00 00 00 02 BA FF
15 01 00 00 00 00 02 C7 CB
15 01 00 00 00 00 02 C8 CB
15 01 00 00 00 00 02 DB CB
15 01 00 00 00 00 02 DC CB
15 01 00 00 00 00 02 FE 00
					05 01 00 00 64 00 01 11
					05 01 00 00 14 00 01 29
					];
				qcom,mdss-dsi-off-command = [
15 01 00 00 00 00 02 FE 76
15 01 00 00 00 00 02 00 04

15 01 00 00 00 00 02 09 28
15 01 00 00 00 00 02 0A 00
15 01 00 00 00 00 02 0B 00
15 01 00 00 00 00 02 0C 49
15 01 00 00 00 00 02 0D 76
15 01 00 00 00 00 02 0E 17

15 01 00 00 00 00 02 49 FF
15 01 00 00 00 00 02 4A 01
15 01 00 00 00 00 02 4B 01
15 01 00 00 00 00 02 4C FE
15 01 00 00 00 00 02 4D 60
15 01 00 00 00 00 02 4E AE
15 01 00 00 00 00 02 4F 28
15 01 00 00 00 00 02 50 B3
15 01 00 00 00 00 02 51 28
15 01 00 00 00 00 02 52 B8
15 01 00 00 00 00 02 53 F9
15 01 00 00 00 00 02 54 BA
15 01 00 00 00 00 02 55 9F
15 01 00 00 00 00 02 56 C7
15 01 00 00 00 00 02 58 CF
15 01 00 00 00 00 02 59 C8
15 01 00 00 00 00 02 5A CF
15 01 00 00 00 00 02 5B DB
15 01 00 00 00 00 02 5C CF
15 01 00 00 00 00 02 5D DC
15 01 00 00 00 00 02 5E CF
15 01 00 00 00 00 02 5F FE
15 01 00 00 00 00 02 60 00
					15 01 00 00 14 00 02 FE 00
					05 01 00 00 93 00 01 28
					05 01 00 00 14 00 01 10
				];
				qcom,mdss-dsi-on-command-state = "dsi_lp_mode";
				qcom,mdss-dsi-off-command-state = "dsi_lp_mode";

				qcom,mdss-dsi-lp1-command = [
					15 01 00 00 00 00 02 FE 00
					05 01 00 00 14 00 01 39
				];
				qcom,mdss-dsi-lp1-command-state =
					"dsi_lp_mode";
				qcom,mdss-dsi-nolp-command = [
					15 01 00 00 00 00 02 FE 00
					39 01 00 00 00 00 03 51 00 00
					05 01 00 00 00 00 01 38
				];
				qcom,mdss-dsi-nolp-command-state =
					"dsi_lp_mode";
				qcom,mdss-dsi-timing-switch-command = [
					39 00 00 40 00 00 02 fe 40
					39 00 00 40 00 00 02 bd 05
					39 00 00 40 00 00 02 FE 5A
					39 00 00 40 00 00 0B 49 0F 08 04 00 06 06 06 06 06 04
					39 00 00 40 00 00 03 55 10 10
					39 00 00 40 00 00 03 58 05 03
					39 00 00 40 00 00 05 5E 0F 0F 0F 0A
					39 00 00 40 00 00 04 66 10 10 10
					39 00 00 40 00 00 03 6E 05 05
					39 00 00 40 00 00 03 76 05 05
					39 00 00 40 00 00 03 7E 05 05
					39 00 00 40 00 00 04 92 72 45 25
					39 00 00 40 00 00 05 99 7F 40 0F 03
					39 00 00 40 00 00 04 9E 30 10 3D
					39 00 00 40 00 00 03 A2 1D 09
					39 00 00 40 00 00 02 A7 27
					39 00 00 40 00 00 03 A9 27 1A
					39 00 00 40 00 00 02 AC 04
					39 00 00 40 00 00 06 B0 20 10 0A 0D 03
					39 00 00 40 00 00 06 B8 12 12 0D 03 02
					39 00 00 40 00 00 05 C0 0E 0E 09 03
					39 00 00 40 00 00 04 C8 0B 0B 07
					39 00 00 40 00 00 02 EA 1F
					39 00 00 40 00 00 02 FE 5B
					39 00 00 40 00 00 02 2B 7A
					39 00 00 40 00 00 02 2D 45
					39 00 00 40 00 00 02 2F 32
					39 00 00 40 00 00 0D 31 60 1F 60 60 60 37 18 0F 0A 30 30 2B
					39 00 00 40 00 00 02 3D 1F
					39 00 00 40 00 00 0B 3F 0F 07 02 01 1B 1B 1B 0E 06 02
					39 00 00 40 00 00 05 4B 13 13 0D 09
					39 00 00 40 00 00 02 50 01
					39 00 00 40 00 00 05 53 12 12 0B 05
					39 00 00 40 00 00 02 58 03
					39 00 00 40 00 00 06 5C 0B 0D 08 04 02
					39 00 00 40 00 00 06 5C 0B 00 08 04 02
					39 00 00 40 00 00 05 64 09 09 06 02
					39 00 00 00 00 00 02 FE 00
				];
				qcom,mdss-dsi-timing-switch-command-state =
				"dsi_lp_mode";
				qcom,compression-mode = "dsc";
				qcom,mdss-dsc-slice-height = <20>;
				qcom,mdss-dsc-slice-width = <558>;
				qcom,mdss-dsc-slice-per-pkt = <2>;
				qcom,mdss-dsc-bit-per-component = <10>;
				qcom,mdss-dsc-bit-per-pixel = <10>;
				qcom,mdss-dsc-block-prediction-enable;
			};
		};
	};
};

/* panel feature */
&dsi_bf068_rm692h0_6p8_magic9_dsc_cmd {
    /* zte disp feature */
	zte,hbm_enabled;
	zte,hdr_enabled;
	zte,fps_enabled;
	zte,aod_enabled;
	zte,acl_enabled;
	zte,color_space_enabled;
	zte,fps_need_blank;
	zte,bl_limit_enabled;
	zte,hdr_video_brightness = <0xFFF>; //hdr brightness
	zte,aod-exit-delay-time = <150>;
	zte,hdr_threshold_list= <0xDBB 0xEE0 0xF6F 0xFFF>; //1100nits
	zte,te-high-width = <8500>;
	qcom,mdss-dsi-display-timings {
		timing@0 {
		   #include "dsi-panel-zte-visionox-rm692h0-common.dtsi"
		};
		timing@1 {
		   #include "dsi-panel-zte-visionox-rm692h0-common.dtsi"
		};
		timing@2 {
		   #include "dsi-panel-zte-visionox-rm692h0-common.dtsi"
		};
	};
};

/* zte dsip power supply */
&dsi_bf068_rm692h0_6p8_magic9_dsc_cmd {
	qcom,panel-supply-entries = <&dsi_panel_pwr_supply_tiro>;
	qcom,mdss-dsi-bl-pmic-control-type = "bl_ctrl_dcs";
	qcom,mdss-brightness-max-level = <2047>;
	qcom,mdss-dsi-bl-inverted-dbv;
	qcom,platform-reset-gpio = <&tlmm 133 0>;
	qcom,ulps-enabled;
	qcom,esd-check-enabled;
	qcom,mdss-dsi-panel-status-check-mode = "reg_read";
	qcom,mdss-dsi-panel-status-command = [
		06 01 00 01 05 00 01 0A
		06 01 00 01 05 00 01 FA];
	qcom,mdss-dsi-panel-status-command-state = "dsi_lp_mode";
	qcom,mdss-dsi-panel-status-value = <0x9c 0x01>;
	qcom,mdss-dsi-panel-status-read-length = <1 1>;
	qcom,dsi-select-clocks = "pll_byte_clk0", "pll_dsi_clk0";
	qcom,mdss-dsi-display-timings {
		timing@0 { /* 60Hz */
			/* DPHY regular margins */
			qcom,mdss-dsi-panel-phy-timings = [00 1E 08 07 18 22
				08 08 08 02 04 00 1A 0D];
			qcom,display-topology = <2 2 1>;
			qcom,default-topology-index = <0>;
		};
		timing@1 { /* 90Hz */
			/* DPHY regular margins */
			qcom,mdss-dsi-panel-phy-timings = [00 2B 0B 0B 1C 27
				0B 0C 0B 02 04 00 23 10];
			qcom,display-topology = <2 2 1>;
			qcom,default-topology-index = <0>;
		};
		timing@2 { /* 120Hz */
			/* DPHY regular margins */
			qcom,mdss-dsi-panel-phy-timings = [00 1E 08 07 18 16
				08 08 08 02 04 00 1A 0D];
			qcom,display-topology = <2 2 1>;
			qcom,default-topology-index = <0>;
		};
	};
};
